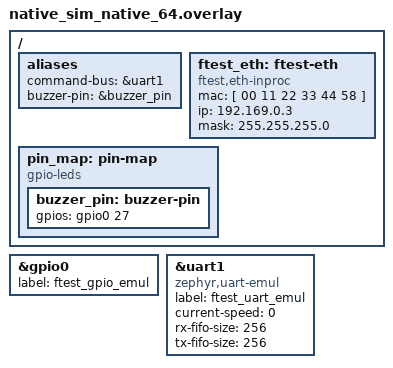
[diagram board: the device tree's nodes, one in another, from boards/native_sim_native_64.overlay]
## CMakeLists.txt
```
# SPDX-License-Identifier: Apache-2.0

cmake_minimum_required(VERSION 3.20.0)

list(APPEND ZEPHYR_EXTRA_MODULES ${CMAKE_CURRENT_SOURCE_DIR}/../_modules/entity_lib)

find_package(Zephyr REQUIRED HINTS $ENV{ZEPHYR_BASE})
project(buzzer)

target_sources(app PRIVATE src/main.c)
```

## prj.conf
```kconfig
CONFIG_EVENTS=y

CONFIG_NO_OPTIMIZATIONS=y
```

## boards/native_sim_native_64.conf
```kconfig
CONFIG_NATIVE_SIM_SLOWDOWN_TO_REAL_TIME=n

CONFIG_GPIO=y
CONFIG_GPIO_EMUL=y

CONFIG_SERIAL=y
CONFIG_EMUL=y

CONFIG_LOG=y
CONFIG_LOG_MAX_LEVEL=4
```

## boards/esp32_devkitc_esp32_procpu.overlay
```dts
/ {
    aliases {
        command-bus =  &uart2;
        buzzer-pin = &buzzer_pin;
    };

    pin_map: pin-map {
        compatible = "gpio-leds";
        buzzer_pin: buzzer-pin {
            gpios = <&gpio0 27 GPIO_ACTIVE_HIGH>;
        };
    };
};

&uart2 {
    status = "okay";
};
```

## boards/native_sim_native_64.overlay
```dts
/ {
    aliases {
        command-bus = &uart1;
        buzzer-pin = &buzzer_pin;
    };

    ftest_eth: ftest-eth {
        status = "okay";
        compatible = "ftest,eth-inproc";
        mac = [ 00 11 22 33 44 58  ];
        ip = "192.169.0.3";
        mask = "255.255.255.0";
    };

    pin_map: pin-map {
        status = "okay";
        compatible = "gpio-leds";
        buzzer_pin: buzzer-pin {
            gpios = <&gpio0 27 GPIO_ACTIVE_HIGH>;
        };
    };
};

&gpio0 {
    status = "okay";
    label = "ftest_gpio_emul";
};

&uart1 {
    status = "okay";
    compatible = "zephyr,uart-emul";
    label = "ftest_uart_emul";
    current-speed = <0>;
    rx-fifo-size = <256>;
    tx-fifo-size = <256>;
};
```

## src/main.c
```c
#include "command_processor.h"
#include "pattern.h"
#include "zephyr/device.h"
#include "zephyr/drivers/gpio.h"
#include "zephyr/drivers/gpio/gpio_emul.h"
#include "zephyr/logging/log.h"
#include <zephyr/kernel.h>

LOG_MODULE_REGISTER(buzzer_main);

#if CONFIG_GPIO_EMUL

static const struct gpio_dt_spec buzzer =
    GPIO_DT_SPEC_GET(DT_ALIAS(buzzer_pin), gpios);

static void logger(void *unused0, void *unused1, void *unused2) {
  while (true) {
    LOG_WRN("Buzzer pin state: %d",
            gpio_emul_output_get(buzzer.port, buzzer.pin));
    k_msleep(10);
  }
}

K_THREAD_DEFINE(logger_thread, 1024, logger, NULL, NULL, NULL,
                K_PRIO_PREEMPT(10), 0, 0);

#endif // CONNFIG_GPIO_EMUL

int play_buzzer_short_beep(void) {
  LOG_INF("Playing short beep");
  buzzer_pattern_start(&pattern_beep_beep);
  return 0;
}

int play_buzzer_long_beep(void) {
  LOG_INF("Playing long beep");
  buzzer_pattern_start(&pattern_beeeeeeee);
  return 0;
}

int stop_buzzer(void) {
  LOG_INF("Stopping buzzer");
  buzzer_pattern_start(&pattern_silence);
  return 0;
}

int main(void) {

  command_processor_register_handler('b', play_buzzer_short_beep);
  command_processor_register_handler('l', play_buzzer_long_beep);
  command_processor_register_handler('s', stop_buzzer);
  return 0;
}
```

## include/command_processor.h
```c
#pragma once

/******************************************************************************
 API
 ******************************************************************************/

void command_processor_register_handler(char command, int (*handler)());
```

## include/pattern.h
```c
#pragma once

#include "zephyr/sys/util_macro.h"
#include <stdint.h>

/******************************************************************************
 Macros
 ******************************************************************************/

#define BUZZER_STEP(...) (__VA_ARGS__)

#define BUZZER_STEP_UNWRAP_IMPL(...) __VA_ARGS__
#define BUZZER_STEP_UNWRAP(...) BUZZER_STEP_UNWRAP_IMPL __VA_ARGS__

#define BUZZER_PATTERN(...)                                                    \
  {                                                                            \
      .step_count = NUM_VA_ARGS(__VA_ARGS__),                                  \
      .steps =                                                                 \
          {                                                                    \
              FOR_EACH(BUZZER_STEP_UNWRAP, (, ), __VA_ARGS__),                 \
          },                                                                   \
  }

/******************************************************************************
 Structures
 ******************************************************************************/

typedef struct {
  uint32_t duration_ms;
  uint32_t loudness;
} buzzer_step_t;

struct buzzer_pattern {
  uint8_t step_count;
  buzzer_step_t steps[UINT8_MAX];
};

/******************************************************************************
 API
 ******************************************************************************/

int buzzer_pattern_start(const struct buzzer_pattern *pattern);

/******************************************************************************
 Patterns
 ******************************************************************************/

extern const struct buzzer_pattern pattern_silence;

extern const struct buzzer_pattern pattern_beep_beep;

extern const struct buzzer_pattern pattern_beeeeeeee;
```

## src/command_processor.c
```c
#include "zephyr/logging/log.h"
#include <limits.h>
#include <string.h>
#include <zephyr/device.h>
#include <zephyr/drivers/uart.h>
#include <zephyr/kernel.h>

/******************************************************************************
 Definitions
 ******************************************************************************/

#define COMMAND_HANDLER_COUNT (UCHAR_MAX + 1)

/******************************************************************************
 Configuration
 ******************************************************************************/

LOG_MODULE_REGISTER(command_processor);

/******************************************************************************
 Data
 ******************************************************************************/

static const struct device *uart = DEVICE_DT_GET(DT_ALIAS(command_bus));

static int (*command_handlers[COMMAND_HANDLER_COUNT])() = {0};

/******************************************************************************
 API
 ******************************************************************************/

void command_processor_register_handler(unsigned char command,
                                        int (*handler)()) {
  command_handlers[command] = handler;
}

/******************************************************************************
 UART Handler Thread
 ******************************************************************************/

static void uart_handler(void) {
  if (!device_is_ready(uart)) {
    LOG_ERR("UART device not ready");
    return;
  }

  LOG_INF("UART command listener started");

  while (1) {
    unsigned char command;
    int res = uart_poll_in(uart, &command);

    if (res < 0) {
      k_msleep(10);
      continue;
    }

    int (*handler)() = command_handlers[command];

    if (handler == NULL) {
      LOG_ERR("Command handler for '%c' not registered", command);
      continue;
    }

    LOG_INF("Executing command handler for '%c'", command);
    res = handler();

    if (res < 0) {
      LOG_ERR("Command handler for '%c' failed with error %d", command, res);
    }
  }
}

K_THREAD_DEFINE(uart_handling_thread, 1024, uart_handler, NULL, NULL, NULL,
                K_PRIO_COOP(5), 0, 0);
```

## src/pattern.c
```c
#include "pattern.h"
#include "zephyr/drivers/gpio.h"
#include "zephyr/kernel.h"
#include "zephyr/logging/log.h"
#include "zephyr/sys_clock.h"

/******************************************************************************
 Definitions
 ******************************************************************************/

LOG_MODULE_REGISTER(pattern_processor);

K_EVENT_DEFINE(pattern_event);

#define PATTERN_EVENT_START BIT(0)

/******************************************************************************
 Data
 ******************************************************************************/

static const struct buzzer_pattern *active_pattern = &pattern_silence;

static const struct gpio_dt_spec buzzer =
    GPIO_DT_SPEC_GET(DT_ALIAS(buzzer_pin), gpios);

/******************************************************************************
 API
 ******************************************************************************/

int buzzer_pattern_start(const struct buzzer_pattern *pattern) {
  active_pattern = pattern;
  k_event_post(&pattern_event, PATTERN_EVENT_START);

  return 0;
}

/******************************************************************************
 Processor thread
 ******************************************************************************/

static void pattern_processor(void *unused0, void *unused1, void *unused2) {
  int res = gpio_pin_configure_dt(&buzzer, GPIO_OUTPUT);

  if (res < 0) {
    LOG_ERR("Configuring buzzer pin failed");
    return;
  }

  k_timeout_t current_iter_duration = Z_FOREVER;
  unsigned current_pattern_step = 0;

  while (true) {
    uint32_t events = k_event_wait(&pattern_event, PATTERN_EVENT_START, false,
                                   current_iter_duration);

    if (events != 0) {
      k_event_clear(&pattern_event, PATTERN_EVENT_START);
      current_pattern_step = 0;

      LOG_INF("Pattern started: %p", active_pattern);
    }

    if (active_pattern == NULL) {
      LOG_ERR("Error - no pattern specified");
      current_iter_duration = Z_FOREVER;
      continue;
    }

    unsigned step_index = current_pattern_step % active_pattern->step_count;
    const buzzer_step_t *step = &active_pattern->steps[step_index];

    int ret = gpio_pin_set_dt(&buzzer, step->loudness > 0);

    if (ret < 0) {
      LOG_ERR("Unable to set output value for buzzer");
    }

    current_iter_duration = Z_TIMEOUT_MS(step->duration_ms);
    current_pattern_step++;
  }
}

K_THREAD_DEFINE(thread_pattern_processor, 2048, pattern_processor, NULL, NULL,
                NULL, K_PRIO_COOP(10), 0, 0);
```

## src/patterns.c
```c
#include "pattern.h"

const struct buzzer_pattern pattern_silence = BUZZER_PATTERN(BUZZER_STEP({
    .duration_ms = UINT32_MAX,
    .loudness = 0,
}));

const struct buzzer_pattern pattern_beep_beep =
    BUZZER_PATTERN(BUZZER_STEP({
                       .duration_ms = 100,
                       .loudness = 100,
                   }),
                   BUZZER_STEP({
                       .duration_ms = 100,
                       .loudness = 0,
                   }),
                   BUZZER_STEP({
                       .duration_ms = 100,
                       .loudness = 100,
                   }),
                   BUZZER_STEP({
                       .duration_ms = 100,
                       .loudness = 0,
                   }));

const struct buzzer_pattern pattern_beeeeeeee =
    BUZZER_PATTERN(BUZZER_STEP({
                       .duration_ms = 500,
                       .loudness = 100,
                   }),
                   BUZZER_STEP({
                       .duration_ms = UINT32_MAX,
                       .loudness = 0,
                   }));
```
